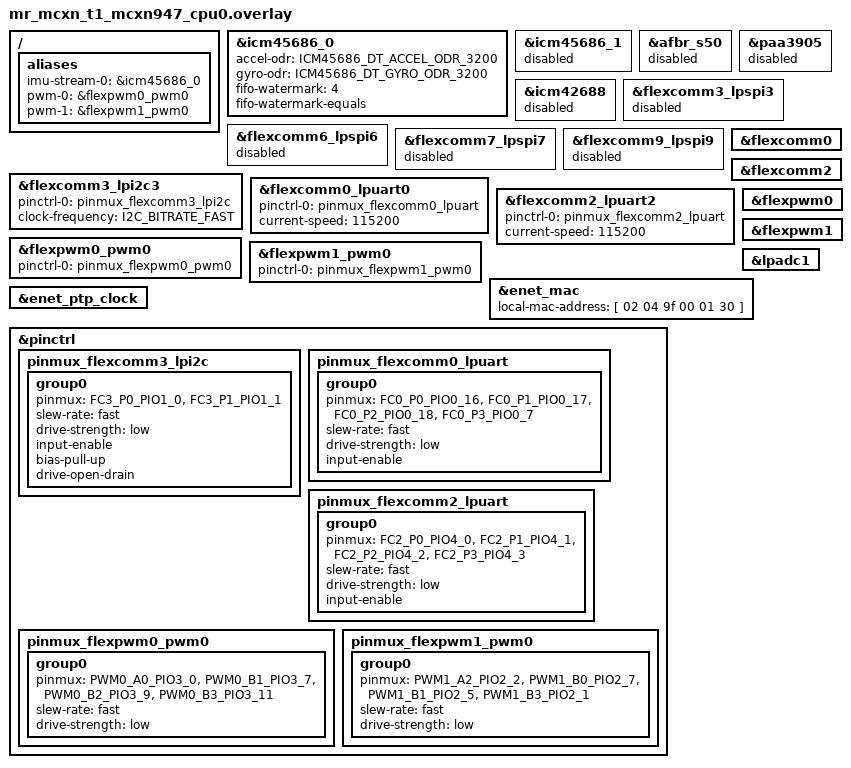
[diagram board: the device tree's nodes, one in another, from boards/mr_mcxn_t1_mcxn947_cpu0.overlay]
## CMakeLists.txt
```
#-------------------------------------------------------------------------------
# Zephyr Spinali Application
#
# Copyright (c) 2023 CogniPilot Foundation
# SPDX-License-Identifier: Apache-2.0

cmake_minimum_required(VERSION 3.13.1)

find_package(Zephyr REQUIRED HINTS $ENV{ZEPHYR_BASE})

project(flex_io LANGUAGES C)

# Validate HCDF SHA at build time
if(DEFINED ZEPHYR_HCDF_MODELS_MODULE_DIR)
  include(${ZEPHYR_HCDF_MODELS_MODULE_DIR}/cmake/hcdf.cmake)
  hcdf_validate_sha(BOARD mr_mcxn_t1 DEVICE flex-io)
endif()

set(flags
  -std=c11
  -Wall
  -Wextra
  -Werror
  -Wstrict-prototypes
  -Waggregate-return
  -Wbad-function-cast
  -Wcast-align
  -Wcast-qual
  -Wfloat-equal
  -Wformat-security
  -Wlogical-op
  -Wmissing-declarations
  -Wmissing-include-dirs
  -Wmissing-prototypes
  -Wnested-externs
  -Wpointer-arith
  -Wredundant-decls
  -Wsequence-point
  -Wshadow
  -Wstrict-prototypes
  -Wswitch
  -Wundef
  -Wunreachable-code
  -Wunused-but-set-parameter
  -Wwrite-strings
  )
string(JOIN " " flags ${flags})

set(SOURCE_FILES
  src/boot_banner.c
  )

set_source_files_properties(
  ${SOURCE_FILES}
  PROPERTIES COMPILE_FLAGS
  "${flags}"
  )

target_sources(app PRIVATE ${SOURCE_FILES})

target_include_directories(app SYSTEM BEFORE PRIVATE ${ZEPHYR_BASE}/include ${CMAKE_BINARY_DIR})

# vi: ts=2 sw=2 et
```

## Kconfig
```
# Copyright (c) 2023, CogniPilot Foundation
# SPDX-License-Identifier: Apache-2.0

mainmenu "CogniPilot - SPINALI - Flex IO"
menu "Zephyr"
source "Kconfig.zephyr"
endmenu

menu "FLEX_IO"

config SPINALI_FLEX_IO_LIGHTING
  bool "enable lighting"
  help
    Enable lighting

module = SPINALI_FLEX_IO
module-str = spinali_flex_io
source "subsys/logging/Kconfig.template.log_config"
endmenu
```

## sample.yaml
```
sample:
  description: flex_io
  name: flex_io
common:
  build_only: true
tests:
  flex_io.mr_mcxn_t1/mcxn947/cpu0:
    tags:
      - flex_io
    integration_platforms:
      - mr_mcxn_t1/mcxn947/cpu0
```

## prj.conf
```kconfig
CONFIG_SPINALI=y
CONFIG_SPINALI_APP_NAME="Flex IO"

CONFIG_ZCBOR=y
CONFIG_MCUMGR=y
CONFIG_MCUMGR_TRANSPORT_UDP=y
CONFIG_MCUMGR_TRANSPORT_UDP_IPV6=y
CONFIG_MCUMGR_GRP_OS=y
CONFIG_MCUMGR_GRP_OS_INFO=y
CONFIG_MCUMGR_GRP_OS_INFO_BUILD_DATE_TIME=y
CONFIG_MCUMGR_GRP_OS_INFO_CUSTOM_HOOKS=y
CONFIG_MCUMGR_MGMT_NOTIFICATION_HOOKS=y
CONFIG_HWINFO=y
CONFIG_MCUMGR_GRP_OS_BOOTLOADER_INFO=y
CONFIG_MCUMGR_GRP_OS_MCUMGR_PARAMS=y
CONFIG_THREAD_MONITOR=y
CONFIG_THREAD_NAME=y
CONFIG_MCUMGR_GRP_OS_TASKSTAT=y
CONFIG_MCUMGR_GRP_OS_TASKSTAT_USE_THREAD_NAME_FOR_NAME=y
CONFIG_THREAD_STACK_INFO=y
CONFIG_FLASH=y
CONFIG_FLASH_MAP=y
CONFIG_IMG_MANAGER=y
CONFIG_STREAM_FLASH=y
CONFIG_MCUMGR_GRP_IMG=y
CONFIG_MCUMGR_GRP_IMG_SLOT_INFO=y
CONFIG_SHELL_BACKEND_DUMMY=y
CONFIG_BASE64=y
CONFIG_MCUMGR_GRP_SHELL=y
CONFIG_STATS=y
CONFIG_STATS_NAMES=y
CONFIG_MCUMGR_GRP_STAT=y
CONFIG_SYS_CLOCK_TICKS_PER_SEC=10000
CONFIG_TICKLESS_KERNEL=n
CONFIG_I3C=n
CONFIG_TEST_RANDOM_GENERATOR=y
CONFIG_FPU=y

CONFIG_NET_BUF_RX_COUNT=24
CONFIG_NET_PKT_RX_COUNT=24

# Sensor streaming
CONFIG_ZROS_SENSE_STREAM=y
CONFIG_ZROS_SENSE_STREAM_IMU=y
# bmm350 mag sits on the disabled i3c bus (i3c_workaround); re-enable when i3c is fixed
CONFIG_ZROS_SENSE_STREAM_MAG=n

# PWM
CONFIG_PWM=y
CONFIG_PWM_SHELL=y

# ADC
CONFIG_ADC=y
CONFIG_ADC_SHELL=y

CONFIG_SHELL=y
CONFIG_SENSOR=y
CONFIG_SENSOR_SHELL=y
CONFIG_SENSOR_INFO=y

CONFIG_SPINALI_SYNAPSE_MCUMGR_HOOKS=y

CONFIG_SPINALI_SYNAPSE_TOPIC=y
CONFIG_SPINALI_CORE_COMMON=y
CONFIG_SPINALI_CORE_COMMON_BOOT_BANNER=y
CONFIG_ZROS=y
CONFIG_SHELL_STACK_SIZE=8192
CONFIG_INIT_STACKS=y

CONFIG_LOG=y
CONFIG_LOG_CMDS=y
CONFIG_LOG_MODE_DEFERRED=y

CONFIG_SPINALI_FLEX_IO_LOG_LEVEL_DBG=y

CONFIG_SENSOR_SHELL_STREAM=y
CONFIG_SENSOR_SHELL_THREAD_STACK_SIZE=8192
CONFIG_SENSOR_LOG_LEVEL_DBG=n

# modules

# General config
CONFIG_MAIN_THREAD_PRIORITY=5
CONFIG_SYSTEM_WORKQUEUE_PRIORITY=-2

# Networking config
CONFIG_NET_SHELL=y
CONFIG_NETWORKING=y
# IPv6-native, router-less peer mesh, no IPv4. The node self-assigns a stable
# EUI-64 interface identifier from its role MAC, so addressing is zero-config
# and reboot-stable with no DHCP and no router. IPv6 MLD is needed to join the
# ff02:: multicast group used for peer discovery.
CONFIG_NET_IPV4=n
CONFIG_NET_IPV6=y
CONFIG_NET_IPV6_MLD=y
CONFIG_NET_IPV6_IID_EUI_64=y
CONFIG_NET_UDP=y
CONFIG_NET_TCP=y
CONFIG_NET_SOCKETS=y
CONFIG_NET_VLAN=y
CONFIG_NET_VLAN_COUNT=1
CONFIG_NET_IF_MAX_IPV6_COUNT=2
CONFIG_NET_CONTEXT_PRIORITY=y
# zenoh-pico session needs a heap pool and enough file descriptors to open
CONFIG_ZVFS_OPEN_MAX=16
CONFIG_HEAP_MEM_POOL_SIZE=32768

# gPTP (IEEE 802.1AS) time sync over the T1 link, as a static timeReceiver:
# the port is pinned to the slave role and the ENET QoS PTP hardware clock
# (PHC) is disciplined from received Sync/Follow_Up alone, so the node locks
# to the grandmaster even through an automotive-profile bridge that sends no
# Announce. NET_GPTP selects PTP_CLOCK and the packet timestamping path
# (NET_L2_PTP_TIMESTAMPING); PTP_CLOCK is listed explicitly to keep the PHC
# in the build if that select ever changes.
CONFIG_NET_GPTP=y
CONFIG_PTP_CLOCK=y
CONFIG_NET_GPTP_STATIC_TIME_RECEIVER=y

# Network address config
CONFIG_NET_HOSTNAME="flex-io"
CONFIG_NET_CONFIG_SETTINGS=y
CONFIG_NET_STATISTICS=y
CONFIG_NET_MGMT_EVENT_INFO=y
CONFIG_NET_MGMT_EVENT_MONITOR=y
CONFIG_NET_BUF_POOL_USAGE=y
CONFIG_NET_DEBUG_NET_PKT_ALLOC=y
CONFIG_NET_CONFIG_NEED_IPV4=n
CONFIG_NET_CONFIG_MY_IPV6_ADDR=""
CONFIG_NET_CONFIG_INIT_TIMEOUT=0

# STATS
CONFIG_THREAD_RUNTIME_STATS=y
CONFIG_SCHED_THREAD_USAGE=y
CONFIG_SCHED_THREAD_USAGE_ANALYSIS=y
CONFIG_SCHED_THREAD_USAGE_ALL=y
CONFIG_SCHED_THREAD_USAGE_AUTO_ENABLE=y

CONFIG_SPEED_OPTIMIZATIONS=y

# Zenoh transport with FlatBuffers. Client session to the host rmw_zenoh
# router over IPv6 UDP on the VLAN mirror path. The router listens on
# udp/[::]:7447 on the VLAN interface (its TCP endpoint is localhost-only),
# so the client connects with a link-local IPv6 UDP locator. The router
# address is a per-deployment input.
CONFIG_SPINALI_SYNAPSE_ZENOH=y
CONFIG_SPINALI_SYNAPSE_ZENOH_LOG_LEVEL_DBG=y
CONFIG_ZENOH_LOCATOR="udp/[fe80::f22f:74ff:fecc:4a66]:7447#iface=vlan0"
CONFIG_ZENOH_PICO=y
CONFIG_ZENOH_PICO_MULTI_THREAD=n
CONFIG_ZENOH_PICO_PUBLICATION=y
CONFIG_ZENOH_PICO_SUBSCRIPTION=y
CONFIG_ZENOH_PICO_QUERY=y
CONFIG_ZENOH_PICO_QUERYABLE=y
CONFIG_ZENOH_PICO_LINK_UDP_UNICAST=y
CONFIG_ZENOH_PICO_LINK_UDP_MULTICAST=n
CONFIG_ZENOH_PICO_SCOUTING=n
```

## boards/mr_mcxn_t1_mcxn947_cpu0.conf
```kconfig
CONFIG_ICM45686_STREAM=y
CONFIG_BMM350_STREAM=y
CONFIG_RTIO_WORKQ_THREADS_POOL_PRIO=4
CONFIG_I2C_RTIO_SQ_SIZE=8
CONFIG_I2C_RTIO_CQ_SIZE=8

# UART
CONFIG_SERIAL=y
CONFIG_UART_INTERRUPT_DRIVEN=y

# I2C
CONFIG_I2C=y
```

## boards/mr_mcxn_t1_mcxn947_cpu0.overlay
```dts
/* SPDX-License-Identifier: Apache-2.0 */
/* Copyright 2025 CogniPilot Foundation */

/ {
	aliases {
		imu-stream-0 = &icm45686_0;
		pwm-0 = &flexpwm0_pwm0;
		pwm-1 = &flexpwm1_pwm0;
	};
};

#include <zephyr/dt-bindings/sensor/icm45686.h>

&icm45686_0 {
	/* Configure to output 4-samples every 1.25-ms (800-Hz) */
	accel-odr = <ICM45686_DT_ACCEL_ODR_3200>;
	gyro-odr = <ICM45686_DT_GYRO_ODR_3200>;
	fifo-watermark = <4>;
	fifo-watermark-equals;
};

/* Disable icm45686_1 - not present on flex_io board */
&icm45686_1 {
	status = "disabled";
};

/* Disable optical flow board sensors - not present on flex_io board */
&afbr_s50 {
	status = "disabled";
};

&paa3905 {
	status = "disabled";
};

&icm42688 {
	status = "disabled";
};

/* Disable optical flow SPI interfaces */
&flexcomm3_lpspi3 {
	status = "disabled";
};

&flexcomm6_lpspi6 {
	status = "disabled";
};

&flexcomm7_lpspi7 {
	status = "disabled";
};

&flexcomm9_lpspi9 {
	status = "disabled";
};

/* Enable I2C on FC3 */
&flexcomm3_lpi2c3 {
	status = "okay";
	pinctrl-0 = <&pinmux_flexcomm3_lpi2c>;
	pinctrl-names = "default";
	clock-frequency = <I2C_BITRATE_FAST>;
};

/* Enable FlexCOMM0 parent for UART */
&flexcomm0 {
	status = "okay";
};

/* Enable UART on FC0 (with flow control) */
&flexcomm0_lpuart0 {
	status = "okay";
	pinctrl-0 = <&pinmux_flexcomm0_lpuart>;
	pinctrl-names = "default";
	current-speed = <115200>;
};

/* Enable FlexCOMM2 parent for UART */
&flexcomm2 {
	status = "okay";
};

/* Enable UART on FC2 (with flow control) */
&flexcomm2_lpuart2 {
	status = "okay";
	pinctrl-0 = <&pinmux_flexcomm2_lpuart>;
	pinctrl-names = "default";
	current-speed = <115200>;
};

/* Enable FlexPWM0 */
&flexpwm0 {
	status = "okay";
};

&flexpwm0_pwm0 {
	status = "okay";
	pinctrl-0 = <&pinmux_flexpwm0_pwm0>;
	pinctrl-names = "default";
};

/* Enable FlexPWM1 */
&flexpwm1 {
	status = "okay";
};

&flexpwm1_pwm0 {
	status = "okay";
	pinctrl-0 = <&pinmux_flexpwm1_pwm0>;
	pinctrl-names = "default";
};

/* ADC1 - TODO: Add channel configuration when needed */
&lpadc1 {
	status = "okay";
};

/* Role-derived interface identity for node 13 (flex_io).
 * Locally administered MAC whose final 12 bits read as the decimal node id
 * followed by a zero in hex, so node 13 is 02:04:9f:00:01:30. The EUI-64
 * IPv6 link-local address follows from it as fe80::4:9fff:fe00:130. The role
 * MAC replaces the silicon-derived nxp,unique-mac from the board dtsi (the
 * enet-qos driver honors local-mac-address only when nxp,unique-mac is
 * absent), so the firmware image is identical across hardware sets. The gPTP
 * clock identity is derived from this MAC, which is intended.
 */
&enet_mac {
	/delete-property/ nxp,unique-mac;
	local-mac-address = [ 02 04 9f 00 01 30 ];
};

/* ENET QoS PTP hardware clock (PHC): disabled by default in the SoC dtsi.
 * Enabled here so the gPTP time-receiver stack has a clock to discipline,
 * putting this node's timestamps on the shared network timescale.
 */
&enet_ptp_clock {
	status = "okay";
};

/* Pinctrl definitions */
&pinctrl {
	/* FC3 I2C (P1_0 SDA, P1_1 SCL) */
	pinmux_flexcomm3_lpi2c: pinmux_flexcomm3_lpi2c {
		group0 {
			pinmux = <FC3_P0_PIO1_0>,
				 <FC3_P1_PIO1_1>;
			slew-rate = "fast";
			drive-strength = "low";
			input-enable;
			bias-pull-up;
			drive-open-drain;
		};
	};

	/* FC0 UART with RTS/CTS */
	pinmux_flexcomm0_lpuart: pinmux_flexcomm0_lpuart {
		group0 {
			pinmux = <FC0_P0_PIO0_16>,
				 <FC0_P1_PIO0_17>,
				 <FC0_P2_PIO0_18>,
				 <FC0_P3_PIO0_7>;
			slew-rate = "fast";
			drive-strength = "low";
			input-enable;
		};
	};

	/* FC2 UART with RTS/CTS */
	pinmux_flexcomm2_lpuart: pinmux_flexcomm2_lpuart {
		group0 {
			pinmux = <FC2_P0_PIO4_0>,
				 <FC2_P1_PIO4_1>,
				 <FC2_P2_PIO4_2>,
				 <FC2_P3_PIO4_3>;
			slew-rate = "fast";
			drive-strength = "low";
			input-enable;
		};
	};

	/* FlexPWM0 channels */
	pinmux_flexpwm0_pwm0: pinmux_flexpwm0_pwm0 {
		group0 {
			pinmux = <PWM0_A0_PIO3_0>,
				 <PWM0_B1_PIO3_7>,
				 <PWM0_B2_PIO3_9>,
				 <PWM0_B3_PIO3_11>;
			slew-rate = "fast";
			drive-strength = "low";
		};
	};

	/* FlexPWM1 channels */
	pinmux_flexpwm1_pwm0: pinmux_flexpwm1_pwm0 {
		group0 {
			pinmux = <PWM1_A2_PIO2_2>,
				 <PWM1_B0_PIO2_7>,
				 <PWM1_B1_PIO2_5>,
				 <PWM1_B3_PIO2_1>;
			slew-rate = "fast";
			drive-strength = "low";
		};
	};

};
```

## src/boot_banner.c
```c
/*
 * Copyright (c) 2023 CogniPilot Foundation
 * SPDX-License-Identifier: Apache-2.0
 */

#include <zephyr/kernel.h>
#include <zephyr/logging/log.h>

#if defined(CONFIG_SPINALI_CORE_COMMON_BOOT_BANNER)
#include <stdio.h>
#endif

#include <spinali/core/common.h>

LOG_MODULE_REGISTER(flex_io_boot_banner, CONFIG_SPINALI_FLEX_IO_LOG_LEVEL);

static int flex_io_boot_banner_sys_init(void)
{
	LOG_INF("Spinali Flex IO %d.%d.%d", CONFIG_SPINALI_VERSION_MAJOR,
		CONFIG_SPINALI_VERSION_MINOR, CONFIG_SPINALI_VERSION_PATCH);
#if defined(CONFIG_SPINALI_CORE_COMMON_BOOT_BANNER)
	printf("%s", banner_spinali);
#endif
	return 0;
};

SYS_INIT(flex_io_boot_banner_sys_init, APPLICATION, 0);

// vi: ts=4 sw=4 et
```
